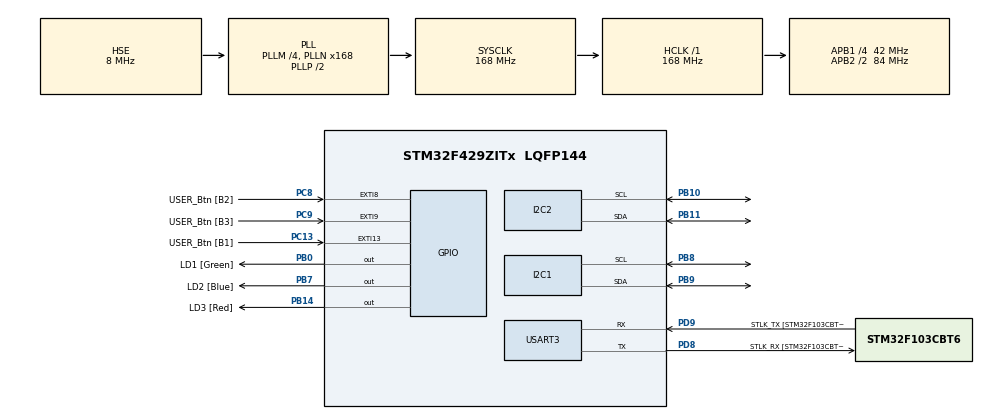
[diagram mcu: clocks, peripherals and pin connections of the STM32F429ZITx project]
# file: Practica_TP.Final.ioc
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Mcu.Family=STM32F4
Mcu.Name=STM32F429ZITx
Mcu.Package=LQFP144
NVIC.PriorityGroup=NVIC_PRIORITYGROUP_4
PA13.GPIO_Label=TMS
PA13.Mode=Serial_Wire
PA13.Signal=SYS_JTMS-SWDIO
PA14.GPIO_Label=TCK
PA14.Mode=Serial_Wire
PA14.Signal=SYS_JTCK-SWCLK
PB0.GPIO_Label=LD1 [Green]
PB0.Signal=GPIO_Output
PB10.Mode=I2C
PB10.Signal=I2C2_SCL
PB11.Mode=I2C
PB11.Signal=I2C2_SDA
PB14.GPIO_Label=LD3 [Red]
PB14.Signal=GPIO_Output
PB7.GPIO_Label=LD2 [Blue]
PB7.Signal=GPIO_Output
PB8.GPIO_Pu=GPIO_NOPULL
PB8.Mode=I2C
PB8.Signal=I2C1_SCL
PB9.GPIO_Pu=GPIO_NOPULL
PB9.Mode=I2C
PB9.Signal=I2C1_SDA
PC13.GPIO_Label=USER_Btn [B1]
PC13.Signal=GPXTI13
PC14/OSC32_IN.Mode=LSE-External-Oscillator
PC14/OSC32_IN.Signal=RCC_OSC32_IN
PC15/OSC32_OUT.Mode=LSE-External-Oscillator
PC15/OSC32_OUT.Signal=RCC_OSC32_OUT
PC8.GPIO_Label=USER_Btn [B2]
PC8.Signal=GPXTI8
PC9.GPIO_Label=USER_Btn [B3]
PC9.Signal=GPXTI9
PD8.GPIO_Label=STLK_RX [STM32F103CBT6_PA3]
PD8.Mode=Asynchronous
PD8.Signal=USART3_TX
PD9.GPIO_Label=STLK_TX [STM32F103CBT6_PA2]
PD9.Mode=Asynchronous
PD9.Signal=USART3_RX
PH0/OSC_IN.GPIO_Label=MCO [STM32F103CBT6_PA8]
PH0/OSC_IN.Mode=HSE-External-Clock-Source
PH0/OSC_IN.Signal=RCC_OSC_IN
PH1/OSC_OUT.Mode=HSE-External-Clock-Source
PH1/OSC_OUT.Signal=RCC_OSC_OUT
ProjectManager.HeapSize=0x200
ProjectManager.StackSize=0x400
ProjectManager.TargetToolchain=STM32CubeIDE
RCC.48MHZClocksFreq_Value=48000000
RCC.AHBFreq_Value=168000000
RCC.APB1CLKDivider=RCC_HCLK_DIV4
RCC.APB1Freq_Value=42000000
RCC.APB1TimFreq_Value=84000000
RCC.APB2CLKDivider=RCC_HCLK_DIV2
RCC.APB2Freq_Value=84000000
RCC.APB2TimCLKDivider=2
RCC.APB2TimFreq_Value=168000000
RCC.CortexFreq_Value=168000000
RCC.HCLKFreq_Value=168000000
RCC.HSE_VALUE=8000000
RCC.HSI_VALUE=16000000
RCC.PLLM=4
RCC.PLLMUL=RCC_PLL_MUL9
RCC.PLLN=168
RCC.PLLQ=7
RCC.PLLSourceVirtual=RCC_PLLSOURCE_HSE
RCC.PRESCALERUSB=RCC_USBCLKSOURCE_PLL_DIV1_5
RCC.SYSCLKFreq_VALUE=168000000
RCC.SYSCLKSource=RCC_SYSCLKSOURCE_PLLCLK
RCC.SYSCLKSourceVirtual=RCC_SYSCLKSOURCE_PLLCLK
RCC.USBFreq_Value=48000000
RCC.VCOOutputFreq_Value=336000000
USART3.VirtualMode=VM_ASYNC
board=NUCLEO-F429ZI

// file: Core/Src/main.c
/* USER CODE BEGIN Header */
/**
  ******************************************************************************
  * @file           : main.c
  * @brief          : Main program body
  ******************************************************************************
  * @attention
  *
  * Copyright (c) 2024 STMicroelectronics.
  * All rights reserved.
  *
  * This software is licensed under terms that can be found in the LICENSE file
  * in the root directory of this software component.
  * If no LICENSE file comes with this software, it is provided AS-IS.
  *
  ******************************************************************************
  */
/* USER CODE END Header */
#include "main.h"

I2C_HandleTypeDef hi2c1;
I2C_HandleTypeDef hi2c2;

UART_HandleTypeDef huart3;

void SystemClock_Config(void);
static void MX_GPIO_Init(void);
static void MX_I2C1_Init(void);
static void MX_I2C2_Init(void);
static void MX_USART3_UART_Init(void);

int main(void)
{

  /* MCU Configuration--------------------------------------------------------*/

  /* Reset of all peripherals, Initializes the Flash interface and the Systick. */
  HAL_Init();

  /* Configure the system clock */
  SystemClock_Config();

  /* Initialize all configured peripherals */
  MX_GPIO_Init();
  MX_I2C1_Init();
  MX_I2C2_Init();
  MX_USART3_UART_Init();
  /* USER CODE BEGIN 2 */

  GPIO_t userButtonC8 = {USER_BtnC8_GPIO_Port, USER_BtnC8_Pin};
  GPIO_t userButtonC9 = {USER_BtnC9_GPIO_Port, USER_BtnC9_Pin};
  FSM_t appFSM = NULL;
  appFSM = APP_FSM_Init(userButtonC8, userButtonC9);

  /* USER CODE END 2 */

  /* Infinite loop */
  /* USER CODE BEGIN WHILE */
  while (1)
  {
    APP_FSM_Update(appFSM);

    /* USER CODE END WHILE */

  }
}

void SystemClock_Config(void)
{
  RCC_OscInitTypeDef RCC_OscInitStruct = {0};
  RCC_ClkInitTypeDef RCC_ClkInitStruct = {0};

  /** Configure the main internal regulator output voltage
  */
  __HAL_RCC_PWR_CLK_ENABLE();
  __HAL_PWR_VOLTAGESCALING_CONFIG(PWR_REGULATOR_VOLTAGE_SCALE1);

  /** Initializes the RCC Oscillators according to the specified parameters
  * in the RCC_OscInitTypeDef structure.
  */
  RCC_OscInitStruct.OscillatorType = RCC_OSCILLATORTYPE_HSE;
  RCC_OscInitStruct.HSEState = RCC_HSE_BYPASS;
  RCC_OscInitStruct.PLL.PLLState = RCC_PLL_ON;
  RCC_OscInitStruct.PLL.PLLSource = RCC_PLLSOURCE_HSE;
  RCC_OscInitStruct.PLL.PLLM = 4;
  RCC_OscInitStruct.PLL.PLLN = 168;
  RCC_OscInitStruct.PLL.PLLP = RCC_PLLP_DIV2;
  RCC_OscInitStruct.PLL.PLLQ = 7;
  if (HAL_RCC_OscConfig(&RCC_OscInitStruct) != HAL_OK)
  {
    Error_Handler();
  }

  /** Initializes the CPU, AHB and APB buses clocks
  */
  RCC_ClkInitStruct.ClockType = RCC_CLOCKTYPE_HCLK|RCC_CLOCKTYPE_SYSCLK
                              |RCC_CLOCKTYPE_PCLK1|RCC_CLOCKTYPE_PCLK2;
  RCC_ClkInitStruct.SYSCLKSource = RCC_SYSCLKSOURCE_PLLCLK;
  RCC_ClkInitStruct.AHBCLKDivider = RCC_SYSCLK_DIV1;
  RCC_ClkInitStruct.APB1CLKDivider = RCC_HCLK_DIV4;
  RCC_ClkInitStruct.APB2CLKDivider = RCC_HCLK_DIV2;

  if (HAL_RCC_ClockConfig(&RCC_ClkInitStruct, FLASH_LATENCY_5) != HAL_OK)
  {
    Error_Handler();
  }
}

static void MX_I2C1_Init(void)
{

  hi2c1.Instance = I2C1;
  hi2c1.Init.ClockSpeed = 100000;
  hi2c1.Init.DutyCycle = I2C_DUTYCYCLE_2;
  hi2c1.Init.OwnAddress1 = 0;
  hi2c1.Init.AddressingMode = I2C_ADDRESSINGMODE_7BIT;
  hi2c1.Init.DualAddressMode = I2C_DUALADDRESS_DISABLE;
  hi2c1.Init.OwnAddress2 = 0;
  hi2c1.Init.GeneralCallMode = I2C_GENERALCALL_DISABLE;
  hi2c1.Init.NoStretchMode = I2C_NOSTRETCH_DISABLE;
  if (HAL_I2C_Init(&hi2c1) != HAL_OK)
  {
    Error_Handler();
  }

  /** Configure Analogue filter
  */
  if (HAL_I2CEx_ConfigAnalogFilter(&hi2c1, I2C_ANALOGFILTER_ENABLE) != HAL_OK)
  {
    Error_Handler();
  }

  /** Configure Digital filter
  */
  if (HAL_I2CEx_ConfigDigitalFilter(&hi2c1, 0) != HAL_OK)
  {
    Error_Handler();
  }

}

static void MX_I2C2_Init(void)
{

  hi2c2.Instance = I2C2;
  hi2c2.Init.ClockSpeed = 100000;
  hi2c2.Init.DutyCycle = I2C_DUTYCYCLE_2;
  hi2c2.Init.OwnAddress1 = 0;
  hi2c2.Init.AddressingMode = I2C_ADDRESSINGMODE_7BIT;
  hi2c2.Init.DualAddressMode = I2C_DUALADDRESS_DISABLE;
  hi2c2.Init.OwnAddress2 = 0;
  hi2c2.Init.GeneralCallMode = I2C_GENERALCALL_DISABLE;
  hi2c2.Init.NoStretchMode = I2C_NOSTRETCH_DISABLE;
  if (HAL_I2C_Init(&hi2c2) != HAL_OK)
  {
    Error_Handler();
  }

  /** Configure Analogue filter
  */
  if (HAL_I2CEx_ConfigAnalogFilter(&hi2c2, I2C_ANALOGFILTER_ENABLE) != HAL_OK)
  {
    Error_Handler();
  }

  /** Configure Digital filter
  */
  if (HAL_I2CEx_ConfigDigitalFilter(&hi2c2, 0) != HAL_OK)
  {
    Error_Handler();
  }

}

static void MX_USART3_UART_Init(void)
{

  huart3.Instance = USART3;
  huart3.Init.BaudRate = 115200;
  huart3.Init.WordLength = UART_WORDLENGTH_8B;
  huart3.Init.StopBits = UART_STOPBITS_1;
  huart3.Init.Parity = UART_PARITY_NONE;
  huart3.Init.Mode = UART_MODE_TX_RX;
  huart3.Init.HwFlowCtl = UART_HWCONTROL_NONE;
  huart3.Init.OverSampling = UART_OVERSAMPLING_16;
  if (HAL_UART_Init(&huart3) != HAL_OK)
  {
    Error_Handler();
  }

}

static void MX_GPIO_Init(void)
{
  GPIO_InitTypeDef GPIO_InitStruct = {0};

  /* GPIO Ports Clock Enable */
  __HAL_RCC_GPIOC_CLK_ENABLE();
  __HAL_RCC_GPIOH_CLK_ENABLE();
  __HAL_RCC_GPIOB_CLK_ENABLE();
  __HAL_RCC_GPIOD_CLK_ENABLE();
  __HAL_RCC_GPIOA_CLK_ENABLE();

  /*Configure GPIO pins : USER_Btn_Pin USER_BtnC8_Pin USER_BtnC9_Pin */
  GPIO_InitStruct.Pin = USER_BtnC8_Pin|USER_BtnC9_Pin;
  GPIO_InitStruct.Mode = GPIO_MODE_IT_RISING;
  GPIO_InitStruct.Pull = GPIO_NOPULL;
  HAL_GPIO_Init(GPIOC, &GPIO_InitStruct);

}

void Error_Handler(void)
{
  __disable_irq();
  while (1)
  {
  }
}
